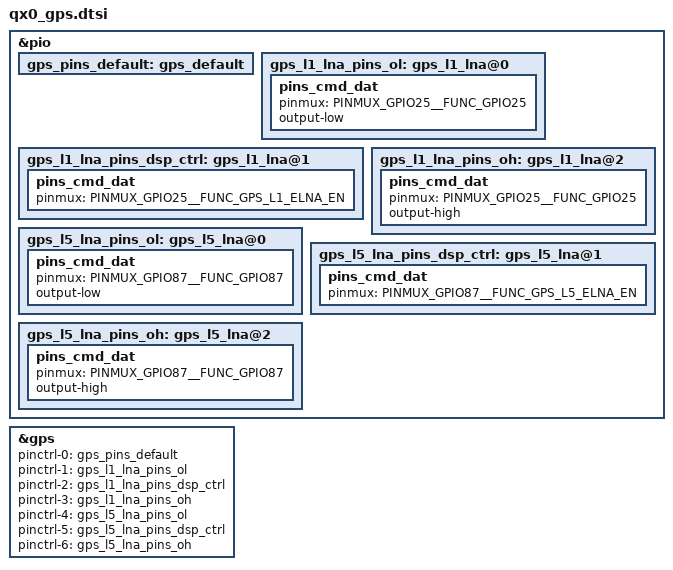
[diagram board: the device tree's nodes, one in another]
&pio {
	gps_pins_default: gps_default {
	};
	gps_l1_lna_pins_ol: gps_l1_lna@0 {
		pins_cmd_dat {
			pinmux = <PINMUX_GPIO25__FUNC_GPIO25>;
			output-low;
		};
	};
	gps_l1_lna_pins_dsp_ctrl: gps_l1_lna@1 {
		pins_cmd_dat {
			pinmux = <PINMUX_GPIO25__FUNC_GPS_L1_ELNA_EN>;
		};
	};
	gps_l1_lna_pins_oh: gps_l1_lna@2 {
		pins_cmd_dat {
			pinmux = <PINMUX_GPIO25__FUNC_GPIO25>;
			output-high;
		};
	};
	gps_l5_lna_pins_ol: gps_l5_lna@0 {
		pins_cmd_dat {
			pinmux = <PINMUX_GPIO87__FUNC_GPIO87>;
			output-low;
		};
	};
	gps_l5_lna_pins_dsp_ctrl: gps_l5_lna@1 {
		pins_cmd_dat {
			pinmux = <PINMUX_GPIO87__FUNC_GPS_L5_ELNA_EN>;
		};
	};
	gps_l5_lna_pins_oh: gps_l5_lna@2 {
		pins_cmd_dat {
			pinmux = <PINMUX_GPIO87__FUNC_GPIO87>;
			output-high;
		};
	};
};

&gps {
	pinctrl-names = "default",
		"gps_l1_lna_disable",
		"gps_l1_lna_dsp_ctrl",
		"gps_l1_lna_enable",
		"gps_l5_lna_disable",
		"gps_l5_lna_dsp_ctrl",
		"gps_l5_lna_enable";
	pinctrl-0 = <&gps_pins_default>;
	pinctrl-1 = <&gps_l1_lna_pins_ol>;
	pinctrl-2 = <&gps_l1_lna_pins_dsp_ctrl>;
	pinctrl-3 = <&gps_l1_lna_pins_oh>;
	pinctrl-4 = <&gps_l5_lna_pins_ol>;
	pinctrl-5 = <&gps_l5_lna_pins_dsp_ctrl>;
	pinctrl-6 = <&gps_l5_lna_pins_oh>;
	status = "okay";
};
